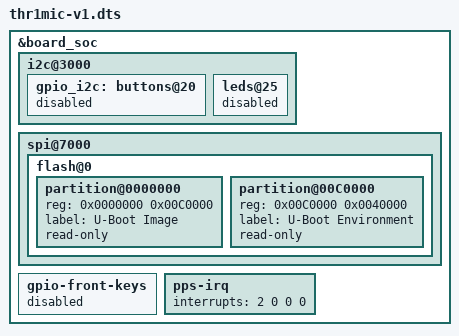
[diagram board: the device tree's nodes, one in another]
/*
 * THR1MIC Device Tree Source
 *
 * Copyright 2018 OMICRON electronics GmbH.
 *
 * This program is free software; you can redistribute	it and/or modify it
 * under  the terms of	the GNU General	 Public License as published by the
 * Free Software Foundation;  either version 2 of the  License, or (at your
 * option) any later version.
 */

/include/ "thr1mic.dts"

&board_soc {
	i2c@3000 {
		/* Only on ETH, revision 2 */
		gpio_i2c: buttons@20 {
			status = "disabled";
		};
		/* Only on ETH, revision 2 */
		leds@25 {
			status = "disabled";
		};
	};

	spi@7000 {
		flash@0 {
			/delete-node/ partition@0000000;
			partition@0000000 { reg = <0x0000000 0x00C0000>; label = "U-Boot Image"; read-only; };
			partition@00C0000 { reg = <0x00C0000 0x0040000>; label = "U-Boot Environment"; read-only; };
		};
	};

	gpio-front-keys {
		status = "disabled";
	};

	pps-irq {
		interrupts = <2 0 0 0>;
	};
};
